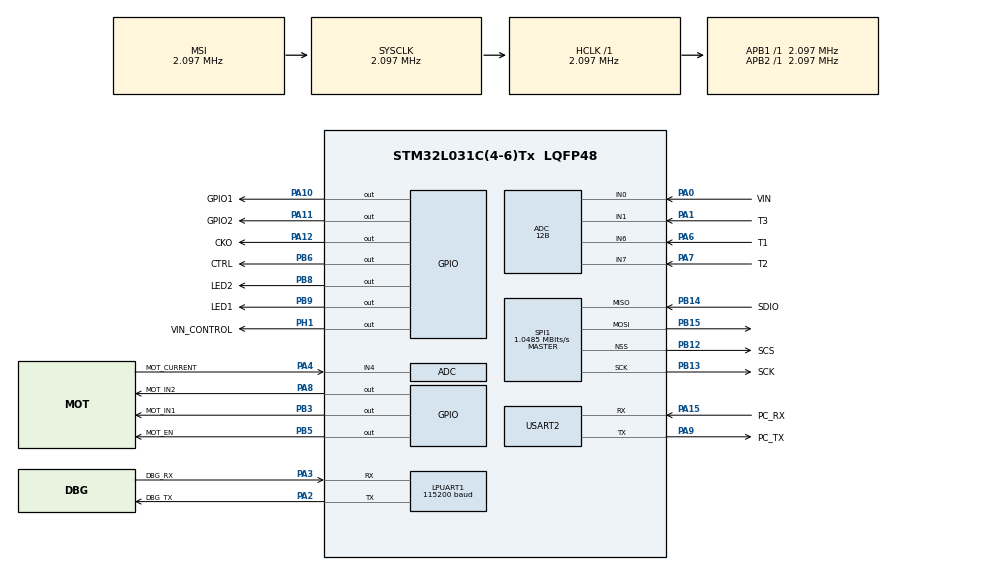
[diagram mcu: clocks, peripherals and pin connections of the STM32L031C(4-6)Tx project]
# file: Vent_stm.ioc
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Mcu.Family=STM32L0
PA6.Mode=IN6
Dma.ADC.0.Mode=DMA_NORMAL
SPI1.VirtualType=VM_MASTER
PB14.GPIO_Label=SDIO
PA0.GPIO_Label=VIN
Dma.ADC.0.Priority=DMA_PRIORITY_LOW
VP_RTC_VS_RTC_Activate.Mode=RTC_Enabled
LPUART1.WordLength=UART_WORDLENGTH_8B
PB6.GPIO_Label=CTRL
PA6.GPIO_Label=T1
PB13.GPIO_Label=SCK
PB15.Signal=SPI1_MOSI
PB13.Signal=SPI1_SCK
ProjectManager.StackSize=0x400
NVIC.RTC_IRQn=true\:0\:0\:false\:false\:true\:true\:true
RTC.WakeUpClock-WakeUp=RTC_WAKEUPCLOCK_CK_SPRE_17BITS
PA15.GPIO_Label=PC_RX
PA12.Signal=GPIO_Output
TIM21.Period=2097
PA4.Mode=IN4
Dma.ADC.0.PeriphInc=DMA_PINC_DISABLE
SPI1.Direction=SPI_DIRECTION_2LINES
RCC.HCLKFreq_Value=2097000
RCC.APB2TimFreq_Value=2097000
PB6.Signal=GPIO_Output
SPI1.CalculateBaudRate=1.0485 MBits/s
RCC.AHBFreq_Value=2097000
Dma.ADC.0.Direction=DMA_PERIPH_TO_MEMORY
ADC.SamplingTime=ADC_SAMPLETIME_7CYCLES_5
RCC.HSE_VALUE=8000000
USART2.VirtualMode-Asynchronous=VM_ASYNC
PA15.Mode=Asynchronous
RCC.RTCClockSelection=RCC_RTCCLKSOURCE_LSE
RCC.PLLMUL=RCC_PLLMUL_4
PB12.GPIO_Label=SCS
LPTIM1.ClockPrescaler=LPTIM_PRESCALER_DIV128
PC14-OSC32_IN.Mode=LSE-External-Oscillator
LPTIM1.UpdateMode=LPTIM_UPDATE_IMMEDIATE
RCC.RTCClockSelectionVirtual=RCC_RTCCLKSOURCE_LSE
PA14.Mode=Serial_Wire
PB14.Mode=Full_Duplex_Master
PA10.GPIO_Label=GPIO1
PA0.Mode=IN0
TIM21.CounterMode=TIM_COUNTERMODE_DOWN
PA8.Signal=GPIO_Output
SPI1.VirtualNSS=VM_NSSHARD
PA0.Signal=ADC_IN0
Dma.ADC.0.MemInc=DMA_MINC_ENABLE
Mcu.Package=LQFP48
PB9.Signal=GPIO_Output
PA6.Signal=ADC_IN6
PB12.Mode=NSS_Signal_Hard_Output
PA2.GPIO_Label=DBG_TX
Dma.ADC.0.Instance=DMA1_Channel1
VP_LPTIM1_VS_LPTIM_counterModeInternalClock.Mode=Counts__internal_clock_event_00
RTC.WakeUpCounter-WakeUp=10
PA10.Signal=GPIO_Output
PA15.Signal=USART2_RX
Dma.ADC.0.MemDataAlignment=DMA_MDATAALIGN_HALFWORD
PB5.GPIO_Label=MOT_EN
ADC.Resolution=ADC_RESOLUTION_12B
RCC.APB1TimFreq_Value=2097000
PB13.Mode=Full_Duplex_Master
Dma.Request0=ADC
PA4.GPIO_Label=MOT_CURRENT
NVIC.RCC_IRQn=true\:0\:0\:false\:false\:true\:true\:false
PA3.Signal=LPUART1_RX
PB3.GPIO_Label=MOT_IN1
RCC.MSI_VALUE=2097000
PC15-OSC32_OUT.Mode=LSE-External-Oscillator
PA7.Mode=IN7
PB9.GPIO_Label=LED1
VP_ADC_TempSens_Input.Mode=IN-TempSens
PA9.GPIO_Label=PC_TX
VP_ADC_Vref_Input.Mode=IN-Vrefint
PA11.GPIO_Label=GPIO2
ADC.LowPowerAutoWait=ENABLE
TIM21.TIM_MasterOutputTrigger=TIM_TRGO_UPDATE
PC14-OSC32_IN.Signal=RCC_OSC32_IN
VP_COMP1_VS_VREFINT.Mode=VREFINT
ADC.ClockPrescaler=ADC_CLOCK_ASYNC_DIV1
PA12.GPIO_Label=CKO
Dma.ADC.0.PeriphDataAlignment=DMA_PDATAALIGN_HALFWORD
LPTIM1.TriggerSource=LPTIM_TRIGSOURCE_SOFTWARE
PA3.Mode=Asynchronous
PA13.Signal=SYS_SWDIO
RCC.HSI16_VALUE=16000000
PB8.GPIO_Label=LED2
PA9.Mode=Asynchronous
PA8.GPIO_Label=MOT_IN2
ProjectManager.TargetToolchain=STM32CubeIDE
PA9.Signal=USART2_TX
PC15-OSC32_OUT.Signal=RCC_OSC32_OUT
PA1.Signal=SharedAnalog_PA1
PB14.Signal=SPI1_MISO
board=custom
RCC.VCOOutputFreq_Value=64000000
PB15.Mode=Full_Duplex_Master
NVIC.LPTIM1_IRQn=true\:0\:0\:false\:false\:true\:true\:true
COMP1.LPTIMConnection=COMP_LPTIMCONNECTION_IN1_ENABLED
COMP1.InvertingInput=COMP_INPUT_MINUS_VREFINT
RCC.APB2Freq_Value=2097000
VP_TIM21_VS_ClockSourceINT.Mode=Internal
SPI1.Mode=SPI_MODE_MASTER
TIM21.AutoReloadPreload=TIM_AUTORELOAD_PRELOAD_ENABLE
TIM21.Prescaler=0
PA1.GPIO_Label=T3
PH1-OSC_OUT.Signal=GPIO_Output
NVIC.TIM21_IRQn=true\:0\:0\:false\:false\:true\:true\:true
PH1-OSC_OUT.GPIO_Label=VIN_CONTROL
PA13.Mode=Serial_Wire
Mcu.Name=STM32L031C(4-6)Tx
LPUART1.BaudRate=115200
RCC.LptimClockSelection=RCC_LPTIM1CLKSOURCE_LSE
PA2.Signal=LPUART1_TX
PB3.Signal=GPIO_Output
PA4.Signal=ADC_IN4
RCC.SYSCLKFreq_VALUE=2097000
PB5.Signal=GPIO_Output
PA7.GPIO_Label=T2
PA11.Signal=GPIO_Output
PA14.Signal=SYS_SWCLK
ProjectManager.HeapSize=0x200
RCC.HSI_VALUE=16000000
VP_RTC_VS_RTC_WakeUp_intern.Mode=WakeUp
SH.SharedAnalog_PA1.1=COMP1_INP,INP
SH.SharedAnalog_PA1.0=ADC_IN1,IN1
PA2.Mode=Asynchronous
PB8.Signal=GPIO_Output
NVIC.DMA1_Channel1_IRQn=true\:0\:0\:false\:false\:true\:false\:true
RCC.APB1Freq_Value=2097000
NVIC.ADC1_COMP_IRQn=true\:0\:0\:false\:false\:true\:true\:true
PB12.Signal=SPI1_NSS
PA3.GPIO_Label=DBG_RX
PA7.Signal=ADC_IN7

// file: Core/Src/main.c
/* USER CODE BEGIN Header */
/**
  ******************************************************************************
  * @file           : main.c
  * @brief          : Main program body
  ******************************************************************************
  * @attention
  *
  * <h2><center>&copy; Copyright (c) 2021 STMicroelectronics.
  * All rights reserved.</center></h2>
  *
  * This software component is licensed by ST under BSD 3-Clause license,
  * the "License"; You may not use this file except in compliance with the
  * License. You may obtain a copy of the License at:
  *                        opensource.org/licenses/BSD-3-Clause
  *
  ******************************************************************************
  */
/* USER CODE END Header */
#include "main.h"

ADC_HandleTypeDef hadc;
DMA_HandleTypeDef hdma_adc;

COMP_HandleTypeDef hcomp1;

LPTIM_HandleTypeDef hlptim1;

UART_HandleTypeDef hlpuart1;
UART_HandleTypeDef huart2;

RTC_HandleTypeDef hrtc;

SPI_HandleTypeDef hspi1;

TIM_HandleTypeDef htim21;

void SystemClock_Config(void);
static void MX_GPIO_Init(void);
static void MX_DMA_Init(void);
static void MX_ADC_Init(void);
static void MX_LPUART1_UART_Init(void);
static void MX_USART2_UART_Init(void);
static void MX_SPI1_Init(void);
static void MX_LPTIM1_Init(void);
static void MX_TIM21_Init(void);
static void MX_COMP1_Init(void);
static void MX_RTC_Init(void);
/* USER CODE BEGIN PFP */
extern void RunSystemTasks(void);
/* USER CODE END PFP */

int main(void)
{

  /* MCU Configuration--------------------------------------------------------*/

  /* Reset of all peripherals, Initializes the Flash interface and the Systick. */
  HAL_Init();

  /* Configure the system clock */
  SystemClock_Config();

  /* Initialize all configured peripherals */
  MX_GPIO_Init();
  MX_DMA_Init();
  MX_ADC_Init();
  MX_LPUART1_UART_Init();
  MX_USART2_UART_Init();
  MX_SPI1_Init();
  MX_LPTIM1_Init();
  MX_TIM21_Init();
  MX_COMP1_Init();
  MX_RTC_Init();

  /* Infinite loop */
  /* USER CODE BEGIN WHILE */
  RunSystemTasks();
  while (1)
  {
    /* USER CODE END WHILE */

  }
}

void SystemClock_Config(void)
{
  RCC_OscInitTypeDef RCC_OscInitStruct = {0};
  RCC_ClkInitTypeDef RCC_ClkInitStruct = {0};
  RCC_PeriphCLKInitTypeDef PeriphClkInit = {0};

  /** Configure the main internal regulator output voltage
  */
  __HAL_PWR_VOLTAGESCALING_CONFIG(PWR_REGULATOR_VOLTAGE_SCALE1);
  /** Configure LSE Drive Capability
  */
  HAL_PWR_EnableBkUpAccess();
  __HAL_RCC_LSEDRIVE_CONFIG(RCC_LSEDRIVE_LOW);
  /** Initializes the RCC Oscillators according to the specified parameters
  * in the RCC_OscInitTypeDef structure.
  */
  RCC_OscInitStruct.OscillatorType = RCC_OSCILLATORTYPE_HSI|RCC_OSCILLATORTYPE_LSE
                              |RCC_OSCILLATORTYPE_MSI;
  RCC_OscInitStruct.LSEState = RCC_LSE_ON;
  RCC_OscInitStruct.HSIState = RCC_HSI_ON;
  RCC_OscInitStruct.HSICalibrationValue = RCC_HSICALIBRATION_DEFAULT;
  RCC_OscInitStruct.MSIState = RCC_MSI_ON;
  RCC_OscInitStruct.MSICalibrationValue = 0;
  RCC_OscInitStruct.MSIClockRange = RCC_MSIRANGE_5;
  RCC_OscInitStruct.PLL.PLLState = RCC_PLL_NONE;
  if (HAL_RCC_OscConfig(&RCC_OscInitStruct) != HAL_OK)
  {
    Error_Handler();
  }
  /** Initializes the CPU, AHB and APB buses clocks
  */
  RCC_ClkInitStruct.ClockType = RCC_CLOCKTYPE_HCLK|RCC_CLOCKTYPE_SYSCLK
                              |RCC_CLOCKTYPE_PCLK1|RCC_CLOCKTYPE_PCLK2;
  RCC_ClkInitStruct.SYSCLKSource = RCC_SYSCLKSOURCE_MSI;
  RCC_ClkInitStruct.AHBCLKDivider = RCC_SYSCLK_DIV1;
  RCC_ClkInitStruct.APB1CLKDivider = RCC_HCLK_DIV1;
  RCC_ClkInitStruct.APB2CLKDivider = RCC_HCLK_DIV1;

  if (HAL_RCC_ClockConfig(&RCC_ClkInitStruct, FLASH_LATENCY_0) != HAL_OK)
  {
    Error_Handler();
  }
  PeriphClkInit.PeriphClockSelection = RCC_PERIPHCLK_USART2|RCC_PERIPHCLK_LPUART1
                              |RCC_PERIPHCLK_RTC|RCC_PERIPHCLK_LPTIM1;
  PeriphClkInit.Usart2ClockSelection = RCC_USART2CLKSOURCE_PCLK1;
  PeriphClkInit.Lpuart1ClockSelection = RCC_LPUART1CLKSOURCE_PCLK1;
  PeriphClkInit.RTCClockSelection = RCC_RTCCLKSOURCE_LSE;
  PeriphClkInit.LptimClockSelection = RCC_LPTIM1CLKSOURCE_LSE;

  if (HAL_RCCEx_PeriphCLKConfig(&PeriphClkInit) != HAL_OK)
  {
    Error_Handler();
  }
}

static void MX_ADC_Init(void)
{

  ADC_ChannelConfTypeDef sConfig = {0};

  /** Configure the global features of the ADC (Clock, Resolution, Data Alignment and number of conversion)
  */
  hadc.Instance = ADC1;
  hadc.Init.OversamplingMode = DISABLE;
  hadc.Init.ClockPrescaler = ADC_CLOCK_ASYNC_DIV1;
  hadc.Init.Resolution = ADC_RESOLUTION_12B;
  hadc.Init.SamplingTime = ADC_SAMPLETIME_7CYCLES_5;
  hadc.Init.ScanConvMode = ADC_SCAN_DIRECTION_FORWARD;
  hadc.Init.DataAlign = ADC_DATAALIGN_RIGHT;
  hadc.Init.ContinuousConvMode = DISABLE;
  hadc.Init.DiscontinuousConvMode = DISABLE;
  hadc.Init.ExternalTrigConvEdge = ADC_EXTERNALTRIGCONVEDGE_NONE;
  hadc.Init.ExternalTrigConv = ADC_SOFTWARE_START;
  hadc.Init.DMAContinuousRequests = DISABLE;
  hadc.Init.EOCSelection = ADC_EOC_SINGLE_CONV;
  hadc.Init.Overrun = ADC_OVR_DATA_PRESERVED;
  hadc.Init.LowPowerAutoWait = ENABLE;
  hadc.Init.LowPowerFrequencyMode = DISABLE;
  hadc.Init.LowPowerAutoPowerOff = DISABLE;
  if (HAL_ADC_Init(&hadc) != HAL_OK)
  {
    Error_Handler();
  }
  /** Configure for the selected ADC regular channel to be converted.
  */
  sConfig.Channel = ADC_CHANNEL_0;
  sConfig.Rank = ADC_RANK_CHANNEL_NUMBER;
  if (HAL_ADC_ConfigChannel(&hadc, &sConfig) != HAL_OK)
  {
    Error_Handler();
  }
  /** Configure for the selected ADC regular channel to be converted.
  */
  sConfig.Channel = ADC_CHANNEL_1;
  if (HAL_ADC_ConfigChannel(&hadc, &sConfig) != HAL_OK)
  {
    Error_Handler();
  }
  /** Configure for the selected ADC regular channel to be converted.
  */
  sConfig.Channel = ADC_CHANNEL_4;
  if (HAL_ADC_ConfigChannel(&hadc, &sConfig) != HAL_OK)
  {
    Error_Handler();
  }
  /** Configure for the selected ADC regular channel to be converted.
  */
  sConfig.Channel = ADC_CHANNEL_6;
  if (HAL_ADC_ConfigChannel(&hadc, &sConfig) != HAL_OK)
  {
    Error_Handler();
  }
  /** Configure for the selected ADC regular channel to be converted.
  */
  sConfig.Channel = ADC_CHANNEL_7;
  if (HAL_ADC_ConfigChannel(&hadc, &sConfig) != HAL_OK)
  {
    Error_Handler();
  }
  /** Configure for the selected ADC regular channel to be converted.
  */
  sConfig.Channel = ADC_CHANNEL_TEMPSENSOR;
  if (HAL_ADC_ConfigChannel(&hadc, &sConfig) != HAL_OK)
  {
    Error_Handler();
  }
  /** Configure for the selected ADC regular channel to be converted.
  */
  sConfig.Channel = ADC_CHANNEL_VREFINT;
  if (HAL_ADC_ConfigChannel(&hadc, &sConfig) != HAL_OK)
  {
    Error_Handler();
  }

}

static void MX_COMP1_Init(void)
{

  hcomp1.Instance = COMP1;
  hcomp1.Init.InvertingInput = COMP_INPUT_MINUS_VREFINT;
  hcomp1.Init.NonInvertingInput = COMP_INPUT_PLUS_IO1;
  hcomp1.Init.LPTIMConnection = COMP_LPTIMCONNECTION_IN1_ENABLED;
  hcomp1.Init.OutputPol = COMP_OUTPUTPOL_NONINVERTED;
  hcomp1.Init.Mode = COMP_POWERMODE_ULTRALOWPOWER;
  hcomp1.Init.WindowMode = COMP_WINDOWMODE_DISABLE;
  hcomp1.Init.TriggerMode = COMP_TRIGGERMODE_NONE;
  if (HAL_COMP_Init(&hcomp1) != HAL_OK)
  {
    Error_Handler();
  }

}

static void MX_LPTIM1_Init(void)
{

  hlptim1.Instance = LPTIM1;
  hlptim1.Init.Clock.Source = LPTIM_CLOCKSOURCE_APBCLOCK_LPOSC;
  hlptim1.Init.Clock.Prescaler = LPTIM_PRESCALER_DIV128;
  hlptim1.Init.Trigger.Source = LPTIM_TRIGSOURCE_SOFTWARE;
  hlptim1.Init.OutputPolarity = LPTIM_OUTPUTPOLARITY_HIGH;
  hlptim1.Init.UpdateMode = LPTIM_UPDATE_IMMEDIATE;
  hlptim1.Init.CounterSource = LPTIM_COUNTERSOURCE_INTERNAL;
  if (HAL_LPTIM_Init(&hlptim1) != HAL_OK)
  {
    Error_Handler();
  }

}

static void MX_LPUART1_UART_Init(void)
{

  hlpuart1.Instance = LPUART1;
  hlpuart1.Init.BaudRate = 115200;
  hlpuart1.Init.WordLength = UART_WORDLENGTH_8B;
  hlpuart1.Init.StopBits = UART_STOPBITS_1;
  hlpuart1.Init.Parity = UART_PARITY_NONE;
  hlpuart1.Init.Mode = UART_MODE_TX_RX;
  hlpuart1.Init.HwFlowCtl = UART_HWCONTROL_NONE;
  hlpuart1.Init.OneBitSampling = UART_ONE_BIT_SAMPLE_DISABLE;
  hlpuart1.AdvancedInit.AdvFeatureInit = UART_ADVFEATURE_NO_INIT;
  if (HAL_UART_Init(&hlpuart1) != HAL_OK)
  {
    Error_Handler();
  }

}

static void MX_USART2_UART_Init(void)
{

  huart2.Instance = USART2;
  huart2.Init.BaudRate = 115200;
  huart2.Init.WordLength = UART_WORDLENGTH_8B;
  huart2.Init.StopBits = UART_STOPBITS_1;
  huart2.Init.Parity = UART_PARITY_NONE;
  huart2.Init.Mode = UART_MODE_TX_RX;
  huart2.Init.HwFlowCtl = UART_HWCONTROL_NONE;
  huart2.Init.OverSampling = UART_OVERSAMPLING_16;
  huart2.Init.OneBitSampling = UART_ONE_BIT_SAMPLE_DISABLE;
  huart2.AdvancedInit.AdvFeatureInit = UART_ADVFEATURE_NO_INIT;
  if (HAL_UART_Init(&huart2) != HAL_OK)
  {
    Error_Handler();
  }

}

static void MX_RTC_Init(void)
{

  /** Initialize RTC Only
  */
  hrtc.Instance = RTC;
  hrtc.Init.HourFormat = RTC_HOURFORMAT_24;
  hrtc.Init.AsynchPrediv = 127;
  hrtc.Init.SynchPrediv = 255;
  hrtc.Init.OutPut = RTC_OUTPUT_DISABLE;
  hrtc.Init.OutPutRemap = RTC_OUTPUT_REMAP_NONE;
  hrtc.Init.OutPutPolarity = RTC_OUTPUT_POLARITY_HIGH;
  hrtc.Init.OutPutType = RTC_OUTPUT_TYPE_OPENDRAIN;
  if (HAL_RTC_Init(&hrtc) != HAL_OK)
  {
    Error_Handler();
  }
  /** Enable the WakeUp
  */
  if (HAL_RTCEx_SetWakeUpTimer_IT(&hrtc, 10, RTC_WAKEUPCLOCK_CK_SPRE_17BITS) != HAL_OK)
  {
    Error_Handler();
  }

}

static void MX_SPI1_Init(void)
{

  /* SPI1 parameter configuration*/
  hspi1.Instance = SPI1;
  hspi1.Init.Mode = SPI_MODE_MASTER;
  hspi1.Init.Direction = SPI_DIRECTION_2LINES;
  hspi1.Init.DataSize = SPI_DATASIZE_8BIT;
  hspi1.Init.CLKPolarity = SPI_POLARITY_LOW;
  hspi1.Init.CLKPhase = SPI_PHASE_1EDGE;
  hspi1.Init.NSS = SPI_NSS_HARD_OUTPUT;
  hspi1.Init.BaudRatePrescaler = SPI_BAUDRATEPRESCALER_2;
  hspi1.Init.FirstBit = SPI_FIRSTBIT_MSB;
  hspi1.Init.TIMode = SPI_TIMODE_DISABLE;
  hspi1.Init.CRCCalculation = SPI_CRCCALCULATION_DISABLE;
  hspi1.Init.CRCPolynomial = 7;
  if (HAL_SPI_Init(&hspi1) != HAL_OK)
  {
    Error_Handler();
  }

}

static void MX_TIM21_Init(void)
{

  TIM_ClockConfigTypeDef sClockSourceConfig = {0};
  TIM_MasterConfigTypeDef sMasterConfig = {0};

  htim21.Instance = TIM21;
  htim21.Init.Prescaler = 0;
  htim21.Init.CounterMode = TIM_COUNTERMODE_DOWN;
  htim21.Init.Period = 2097;
  htim21.Init.ClockDivision = TIM_CLOCKDIVISION_DIV1;
  htim21.Init.AutoReloadPreload = TIM_AUTORELOAD_PRELOAD_ENABLE;
  if (HAL_TIM_Base_Init(&htim21) != HAL_OK)
  {
    Error_Handler();
  }
  sClockSourceConfig.ClockSource = TIM_CLOCKSOURCE_INTERNAL;
  if (HAL_TIM_ConfigClockSource(&htim21, &sClockSourceConfig) != HAL_OK)
  {
    Error_Handler();
  }
  sMasterConfig.MasterOutputTrigger = TIM_TRGO_UPDATE;
  sMasterConfig.MasterSlaveMode = TIM_MASTERSLAVEMODE_DISABLE;
  if (HAL_TIMEx_MasterConfigSynchronization(&htim21, &sMasterConfig) != HAL_OK)
  {
    Error_Handler();
  }

}

static void MX_DMA_Init(void)
{

  /* DMA controller clock enable */
  __HAL_RCC_DMA1_CLK_ENABLE();

  /* DMA interrupt init */
  /* DMA1_Channel1_IRQn interrupt configuration */
  HAL_NVIC_SetPriority(DMA1_Channel1_IRQn, 0, 0);
  HAL_NVIC_EnableIRQ(DMA1_Channel1_IRQn);

}

static void MX_GPIO_Init(void)
{
  GPIO_InitTypeDef GPIO_InitStruct = {0};

  /* GPIO Ports Clock Enable */
  __HAL_RCC_GPIOC_CLK_ENABLE();
  __HAL_RCC_GPIOH_CLK_ENABLE();
  __HAL_RCC_GPIOA_CLK_ENABLE();
  __HAL_RCC_GPIOB_CLK_ENABLE();

  /*Configure GPIO pin Output Level */
  HAL_GPIO_WritePin(VIN_CONTROL_GPIO_Port, VIN_CONTROL_Pin, GPIO_PIN_RESET);

  /*Configure GPIO pin Output Level */
  HAL_GPIO_WritePin(GPIOA, MOT_IN2_Pin|GPIO1_Pin|GPIO2_Pin|CKO_Pin, GPIO_PIN_RESET);

  /*Configure GPIO pin Output Level */
  HAL_GPIO_WritePin(GPIOB, MOT_IN1_Pin|MOT_EN_Pin|CTRL_Pin|LED2_Pin
                          |LED1_Pin, GPIO_PIN_RESET);

  /*Configure GPIO pin : VIN_CONTROL_Pin */
  GPIO_InitStruct.Pin = VIN_CONTROL_Pin;
  GPIO_InitStruct.Mode = GPIO_MODE_OUTPUT_PP;
  GPIO_InitStruct.Pull = GPIO_NOPULL;
  GPIO_InitStruct.Speed = GPIO_SPEED_FREQ_LOW;
  HAL_GPIO_Init(VIN_CONTROL_GPIO_Port, &GPIO_InitStruct);

  /*Configure GPIO pins : MOT_IN2_Pin GPIO1_Pin GPIO2_Pin CKO_Pin */
  GPIO_InitStruct.Pin = MOT_IN2_Pin|GPIO1_Pin|GPIO2_Pin|CKO_Pin;
  GPIO_InitStruct.Mode = GPIO_MODE_OUTPUT_PP;
  GPIO_InitStruct.Pull = GPIO_NOPULL;
  GPIO_InitStruct.Speed = GPIO_SPEED_FREQ_LOW;
  HAL_GPIO_Init(GPIOA, &GPIO_InitStruct);

  /*Configure GPIO pins : MOT_IN1_Pin MOT_EN_Pin CTRL_Pin LED2_Pin
                           LED1_Pin */
  GPIO_InitStruct.Pin = MOT_IN1_Pin|MOT_EN_Pin|CTRL_Pin|LED2_Pin
                          |LED1_Pin;
  GPIO_InitStruct.Mode = GPIO_MODE_OUTPUT_PP;
  GPIO_InitStruct.Pull = GPIO_NOPULL;
  GPIO_InitStruct.Speed = GPIO_SPEED_FREQ_LOW;
  HAL_GPIO_Init(GPIOB, &GPIO_InitStruct);

}

void Error_Handler(void)
{
  __disable_irq();
  while (1)
  {
  }
}

/************************ (C) COPYRIGHT STMicroelectronics *****END OF FILE****/
